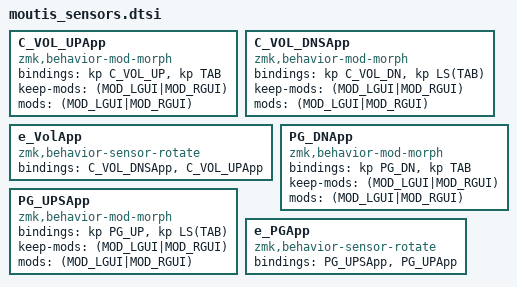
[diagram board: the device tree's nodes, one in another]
/*
 * moutis_sensors.dtsi
 *
 * SPDX-License-Identifier: MIT
 *
 * e_ = EC11 sensor behavior
 *
 */

        C_VOL_UPApp: C_VOL_UPApp {
            compatible = "zmk,behavior-mod-morph";
            #binding-cells = <0>;
            bindings = <&kp C_VOL_UP>, <&kp TAB>;
            keep-mods = <(MOD_LGUI|MOD_RGUI)>;
            mods = <(MOD_LGUI|MOD_RGUI)>;
        };
        C_VOL_DNSApp: C_VOL_DNSApp {
            compatible = "zmk,behavior-mod-morph";
            #binding-cells = <0>;
            bindings = <&kp C_VOL_DN>, <&kp LS(TAB)>;
            keep-mods = <(MOD_LGUI|MOD_RGUI)>;
            mods = <(MOD_LGUI|MOD_RGUI)>;
        };
        e_VolApp: e_VolApp {
            compatible = "zmk,behavior-sensor-rotate";
            #sensor-binding-cells = <0>;
            bindings = <&C_VOL_DNSApp>, <&C_VOL_UPApp>;
        };

        PG_DNApp: PG_DNApp {
            compatible = "zmk,behavior-mod-morph";
            #binding-cells = <0>;
            bindings = <&kp PG_DN>, <&kp TAB>;
            keep-mods = <(MOD_LGUI|MOD_RGUI)>;
            mods = <(MOD_LGUI|MOD_RGUI)>;
        };
        PG_UPSApp: PG_UPSApp {
            compatible = "zmk,behavior-mod-morph";
            #binding-cells = <0>;
            bindings = <&kp PG_UP>, <&kp LS(TAB)>;
            keep-mods = <(MOD_LGUI|MOD_RGUI)>;
            mods = <(MOD_LGUI|MOD_RGUI)>;
        };
        e_PGApp: e_PGApp {
            compatible = "zmk,behavior-sensor-rotate";
            #sensor-binding-cells = <0>;
            bindings = <&PG_UPSApp>, <&PG_UPApp>;
        };
